# ESP32-H2 register map
Vendor: ESPRESSIF SYSTEMS (SHANGHAI) CO., LTD.; Series: ESP32 H-Series; File version: 1
CPU: RV32IMC r0p0, little endian, no MPU, no FPU, 4 interrupt priority bits
Address unit: 32 bits
Registers are 32-bit, read-write, reset 0x0 unless marked. A register's access mark holds for its fields unless they carry their own. Offsets are from the block's base; [hi:lo] are bit positions; {n}, {i} and the like mark numbered series.

## HMAC — HMAC (Hash-based Message Authentication Code) Accelerator
Base 0x6003E000
0x40 SET_START wo — Process control register 0.
  [0] SET_START — Start hmac operation.
0x44 SET_PARA_PURPOSE wo — Configure purpose.
  [3:0] PURPOSE_SET — Set hmac parameter purpose.
0x48 SET_PARA_KEY wo — Configure key.
  [2:0] KEY_SET — Set hmac parameter key.
0x4C SET_PARA_FINISH wo — Finish initial configuration.
  [0] SET_PARA_END — Finish hmac configuration.
0x50 SET_MESSAGE_ONE wo — Process control register 1.
  [0] SET_TEXT_ONE — Call SHA to calculate one message block.
0x54 SET_MESSAGE_ING wo — Process control register 2.
  [0] SET_TEXT_ING — Continue typical hmac.
0x58 SET_MESSAGE_END wo — Process control register 3.
  [0] SET_TEXT_END — Start hardware padding.
0x5C SET_RESULT_FINISH wo — Process control register 4.
  [0] SET_RESULT_END — After read result from upstream, then let hmac back to idle.
0x60 SET_INVALIDATE_JTAG wo — Invalidate register 0.
  [0] SET_INVALIDATE_JTAG — Clear result from hmac downstream JTAG.
0x64 SET_INVALIDATE_DS wo — Invalidate register 1.
  [0] SET_INVALIDATE_DS — Clear result from hmac downstream DS.
0x68 QUERY_ERROR ro — Error register.
  [0] QUREY_CHECK — Hmac configuration state. 0: key are agree with purpose. 1: error
0x6C QUERY_BUSY ro — Busy register.
  [0] BUSY_STATE — Hmac state. 1'b0: idle. 1'b1: busy
{0x80+i} WR_MESSAGE_MEM[{i}] (i=0..63) 8-bit access not given — Message block memory.
{0xC0+i} RD_RESULT_MEM[{i}] (i=0..31) 8-bit access not given — Result from upstream.
0xF0 SET_MESSAGE_PAD wo — Process control register 5.
  [0] SET_TEXT_PAD — Start software padding.
0xF4 ONE_BLOCK wo — Process control register 6.
  [0] SET_ONE_BLOCK — Don't have to do padding.
0xF8 SOFT_JTAG_CTRL wo — Jtag register 0.
  [0] SOFT_JTAG_CTRL — Turn on JTAG verification.
0xFC WR_JTAG wo — Jtag register 1.
  [31:0] WR_JTAG — 32-bit of key to be compared.
0x1FC DATE reset 0x20200618
  [29:0] DATE — Hmac date information/ hmac version information.

## IO_MUX — Input/Output Multiplexer
Base 0x60009000
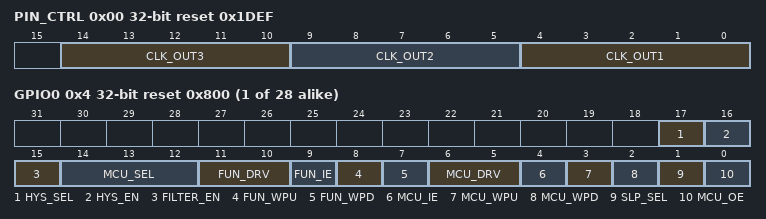
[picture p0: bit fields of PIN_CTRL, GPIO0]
0x00 PIN_CTRL reset 0x1DEF — Clock Output Configuration Register
  [14:10] CLK_OUT3 — If you want to output clock for I2S to CLK_OUT_out3, set this register to 0x0. CLK_OUT_out3 can be found in peripheral output signals.
  [9:5] CLK_OUT2 — If you want to output clock for I2S to CLK_OUT_out2, set this register to 0x0. CLK_OUT_out2 can be found in peripheral output signals.
  [4:0] CLK_OUT1 — If you want to output clock for I2S to CLK_OUT_out1, set this register to 0x0. CLK_OUT_out1 can be found in peripheral output signals.
{0x4+4i} GPIO{i} (i=0..27) reset 0x800 — IO MUX Configure Register for pad GPIO0
  [17] HYS_SEL — Select enabling signals of the pad from software and efuse hardware. 1: Select enabling siganl from slftware. 0: Select enabling signal from efuse hardware.
  [16] HYS_EN — Software enables hysteresis function for the pad. 1: Hysteresis enabled. 0: Hysteresis disabled.
  [15] FILTER_EN — Enable filter for pin input signals. 1: Filter enabled. 0: Filter disabled.
  [14:12] MCU_SEL — Select IO MUX function for this signal. 0: Select Function 1. 1: Select Function 2. etc.
  [11:10] FUN_DRV — Select the drive strength of the pad. 0: ~5 mA. 1: ~10mA. 2: ~20mA. 3: ~40mA.
  [9] FUN_IE — Input enable of the pad. 1: input enabled. 0: input disabled.
  [8] FUN_WPU — Pull-up enable of the pad. 1: internal pull-up enabled. 0: internal pull-up disabled.
  [7] FUN_WPD — Pull-down enable of the pad. 1: internal pull-down enabled. 0: internal pull-down disabled.
  [6:5] MCU_DRV — Select the drive strength of the pad during sleep mode. 0: ~5 mA. 1: ~10mA. 2: ~20mA. 3: ~40mA.
  [4] MCU_IE — Input enable of the pad during sleep mode. 1: input enabled. 0: input disabled.
  [3] MCU_WPU — Pull-up enable of the pad during sleep mode. 1: internal pull-up enabled. 0: internal pull-up disabled.
  [2] MCU_WPD — Pull-down enable of the pad in sleep mode. 1: internal pull-down enabled. 0: internal pull-down disabled.
  [1] SLP_SEL — Sleep mode selection of this pad. Set to 1 to put the pad in pad mode.
  [0] MCU_OE — Output enable of the pad in sleep mode. 1: output enabled. 0: output disabled.
0xBC MODEM_DIAG_EN — GPIO MATRIX Configure Register for modem diag
  [31:0] MODEM_DIAG_EN — bit i to enable modem_diag[i] into gpio matrix. 1:enable modem_diag[i] into gpio matrix. 0:enable other signals into gpio matrix
0xFC DATE reset 0x2207270 — IO MUX Version Control Register
  [27:0] REG_DATE — Version control register
